# ATSAMC21N17A register map
Vendor: Atmel Corporation; Series: SAMC21; File version: A
CPU: CM0+ r0p1, little endian, MPU, no FPU, VTOR, 2 interrupt priority bits
Registers are 32-bit, read-write, reset 0x0 unless marked. A register's access mark holds for its fields unless they carry their own. Offsets are from the block's base; [hi:lo] are bit positions; {n}, {i} and the like mark numbered series.

## MCLK — Main Clock
Base 0x40000800; register names take the prefix MCLK_
0x01 INTENCLR 8-bit — Interrupt Enable Clear
  [0] CKRDY — Clock Ready Interrupt Enable
0x02 INTENSET 8-bit — Interrupt Enable Set
  [0] CKRDY — Clock Ready Interrupt Enable
0x03 INTFLAG 8-bit reset 0x1 — Interrupt Flag Status and Clear
  [0] CKRDY — Clock Ready
0x04 CPUDIV 8-bit reset 0x1 — CPU Clock Division
  [7:0] CPUDIV — CPU Clock Division Factor
    1=DIV1 (Divide by 1); 2=DIV2 (Divide by 2); 4=DIV4 (Divide by 4); 8=DIV8 (Divide by 8); 16=DIV16 (Divide by 16); 32=DIV32 (Divide by 32); 64=DIV64 (Divide by 64); 128=DIV128 (Divide by 128)
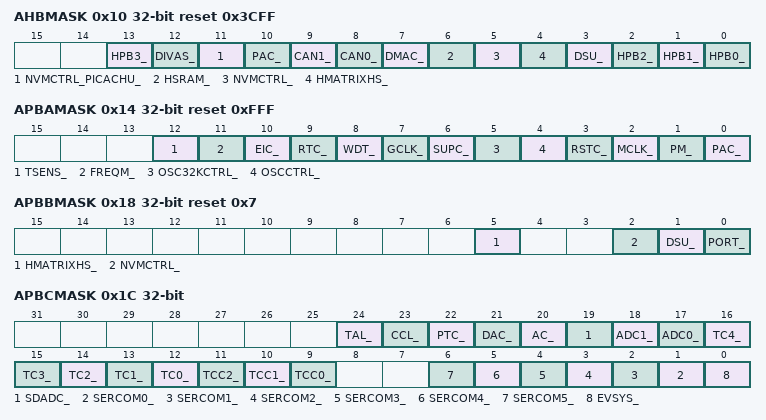
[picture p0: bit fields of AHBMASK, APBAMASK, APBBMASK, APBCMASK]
0x10 AHBMASK reset 0x3CFF
  [13] HPB3_ — HPB3 AHB Clock Mask
  [12] DIVAS_ — DIVAS AHB Clock Mask
  [11] NVMCTRL_PICACHU_ — NVMCTRL_PICACHU AHB Clock Mask
  [10] PAC_ — PAC AHB Clock Mask
  [9] CAN1_ — CAN1 AHB Clock Mask
  [8] CAN0_ — CAN0 AHB Clock Mask
  [7] DMAC_ — DMAC AHB Clock Mask
  [6] HSRAM_ — HSRAM AHB Clock Mask
  [5] NVMCTRL_ — NVMCTRL AHB Clock Mask
  [4] HMATRIXHS_ — HMATRIXHS AHB Clock Mask
  [3] DSU_ — DSU AHB Clock Mask
  [2] HPB2_ — HPB2 AHB Clock Mask
  [1] HPB1_ — HPB1 AHB Clock Mask
  [0] HPB0_ — HPB0 AHB Clock Mask
0x14 APBAMASK reset 0xFFF
  [12] TSENS_ — TSENS APB Clock Enable
  [11] FREQM_ — FREQM APB Clock Enable
  [10] EIC_ — EIC APB Clock Enable
  [9] RTC_ — RTC APB Clock Enable
  [8] WDT_ — WDT APB Clock Enable
  [7] GCLK_ — GCLK APB Clock Enable
  [6] SUPC_ — SUPC APB Clock Enable
  [5] OSC32KCTRL_ — OSC32KCTRL APB Clock Enable
  [4] OSCCTRL_ — OSCCTRL APB Clock Enable
  [3] RSTC_ — RSTC APB Clock Enable
  [2] MCLK_ — MCLK APB Clock Enable
  [1] PM_ — PM APB Clock Enable
  [0] PAC_ — PAC APB Clock Enable
0x18 APBBMASK reset 0x7
  [5] HMATRIXHS_ — HMATRIXHS APB Clock Enable
  [2] NVMCTRL_ — NVMCTRL APB Clock Enable
  [1] DSU_ — DSU APB Clock Enable
  [0] PORT_ — PORT APB Clock Enable
0x1C APBCMASK
  [24] TAL_ — TAL APB Clock Enable
  [23] CCL_ — CCL APB Clock Enable
  [22] PTC_ — PTC APB Clock Enable
  [21] DAC_ — DAC APB Clock Enable
  [20] AC_ — AC APB Clock Enable
  [19] SDADC_ — SDADC APB Clock Enable
  [18] ADC1_ — ADC1 APB Clock Enable
  [17] ADC0_ — ADC0 APB Clock Enable
  [n+12] TC{n}_ (n=0..4) — TC{n} APB Clock Enable
  [11] TCC2_ — TCC2 APB Clock Enable
  [10] TCC1_ — TCC1 APB Clock Enable
  [9] TCC0_ — TCC0 APB Clock Enable
  [n+1] SERCOM{n}_ (n=0..5) — SERCOM{n} APB Clock Enable
  [0] EVSYS_ — EVSYS APB Clock Enable
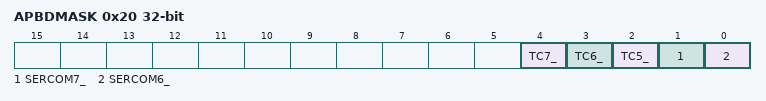
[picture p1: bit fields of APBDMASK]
0x20 APBDMASK
  [4] TC7_ — TC7 APB Clock Enable
  [3] TC6_ — TC6 APB Clock Enable
  [2] TC5_ — TC5 APB Clock Enable
  [1] SERCOM7_ — SERCOM7 APB Clock Enable
  [0] SERCOM6_ — SERCOM6 APB Clock Enable

## MTB — Cortex-M0+ Micro-Trace Buffer
Base 0x41008000; register names take the prefix MTB_
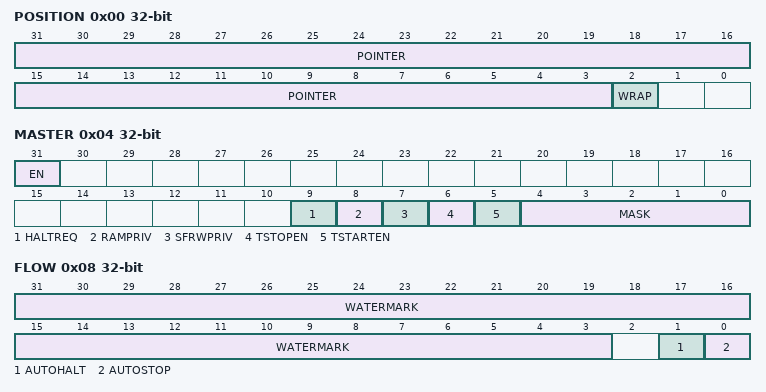
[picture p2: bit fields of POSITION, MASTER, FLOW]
0x00 POSITION — MTB Position
  [31:3] POINTER — Trace Packet Location Pointer
  [2] WRAP — Pointer Value Wraps
0x04 MASTER — MTB Master
  [31] EN — Main Trace Enable
  [9] HALTREQ — Halt Request
  [8] RAMPRIV — SRAM Privilege
  [7] SFRWPRIV — Special Function Register Write Privilege
  [6] TSTOPEN — Trace Stop Input Enable
  [5] TSTARTEN — Trace Start Input Enable
  [4:0] MASK — Maximum Value of the Trace Buffer in SRAM
0x08 FLOW — MTB Flow
  [31:3] WATERMARK — Watermark value
  [1] AUTOHALT — Auto Halt Request
  [0] AUTOSTOP — Auto Stop Tracing
0x0C BASE ro — MTB Base
0xF00 ITCTRL — MTB Integration Mode Control
0xFA0 CLAIMSET — MTB Claim Set
0xFA4 CLAIMCLR — MTB Claim Clear
0xFB0 LOCKACCESS — MTB Lock Access
0xFB4 LOCKSTATUS ro — MTB Lock Status
0xFB8 AUTHSTATUS ro — MTB Authentication Status
0xFBC DEVARCH ro — MTB Device Architecture
0xFC8 DEVID ro — MTB Device Configuration
0xFCC DEVTYPE ro — MTB Device Type
{0xFC0+4i} PID{i} ro (i=4..7) — Peripheral Identification {i}
{0xFE0+4i} PID{i} ro (i=0..3) — Peripheral Identification {i}
{0xFF0+4i} CID{i} ro (i=0..3) — Component Identification {i}

## Notices in the file
Atmel Microcontroller Software Support
Copyright (c) 2017 Atmel Corporation,
a wholly owned subsidiary of Microchip Technology Inc.
Licensed under the Apache License, Version 2.0 (the "License");
you may not use this file except in compliance with the License.
You may obtain a copy of the Licence at
http://www.apache.org/licenses/LICENSE-2.0
Unless required by applicable law or agreed to in writing, software
distributed under the License is distributed on an "AS IS" BASIS,
WITHOUT WARRANTIES OR CONDITIONS OF ANY KIND, either express or implied.
See the License for the specific language governing permissions and
limitations under the License.
